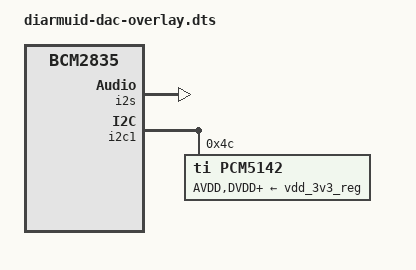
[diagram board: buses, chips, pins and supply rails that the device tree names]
// Definitions for Diarmuid DAC
/dts-v1/;
/plugin/;

/ {
	compatible = "brcm,bcm2835";

	fragment@0 {
		target-path = "/";
		__overlay__ {
			dacpro_osc: dacpro_osc {
				compatible = "hifiberry,dacpro-clk";
				#clock-cells = <0>;
			};
		};
	};

	fragment@1 {
		target = <&i2s>;
		__overlay__ {
			status = "okay";
		};
	};

	fragment@2 {
		target = <&i2c1>;
		__overlay__ {
			#address-cells = <1>;
			#size-cells = <0>;
			status = "okay";

			pcm5142@4c {
				#sound-dai-cells = <0>;
				compatible = "ti,pcm5142";
				reg = <0x4c>;
				clocks = <&dacpro_osc>;
				AVDD-supply = <&vdd_3v3_reg>;
				DVDD-supply = <&vdd_3v3_reg>;
				CPVDD-supply = <&vdd_3v3_reg>;
				status = "okay";
			};
		};
	};

	fragment@3 {
		target = <&sound>;
		diarmuid_dac: __overlay__ {
			compatible = "hifiberry,hifiberry-dacplus";
			i2s-controller = <&i2s>;
			status = "okay";
		};
	};

	__overrides__ {
		24db_digital_gain =
			<&diarmuid_dac>,"hifiberry,24db_digital_gain?";
		slave = <&diarmuid_dac>,"hifiberry-dacplus,slave?";
		leds_off = <&diarmuid_dac>,"hifiberry-dacplus,leds_off?";
	};
};
